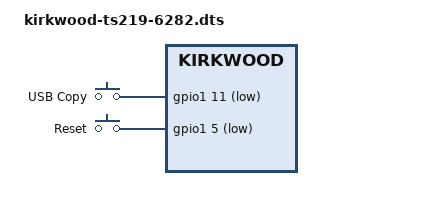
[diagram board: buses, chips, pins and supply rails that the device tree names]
/dts-v1/;

/include/ "kirkwood-ts219.dtsi"

/ {
	ocp@f1000000 {
		egiga0 {
			compatible = "marvell,mv643xx";
			mdio = <&smi0>;
			port_number = <0>;
			phy_addr = <0x80>;
			interrupts = <11>;
		};
	};
	gpio_keys {
		compatible = "gpio-keys";
		#address-cells = <1>;
		#size-cells = <0>;
		button@1 {
			label = "USB Copy";
			linux,code = <133>;
			gpios = <&gpio1 11 1>;
		};
		button@2 {
			label = "Reset";
			linux,code = <0x198>;
			gpios = <&gpio1 5 1>;
		};
	};
};
